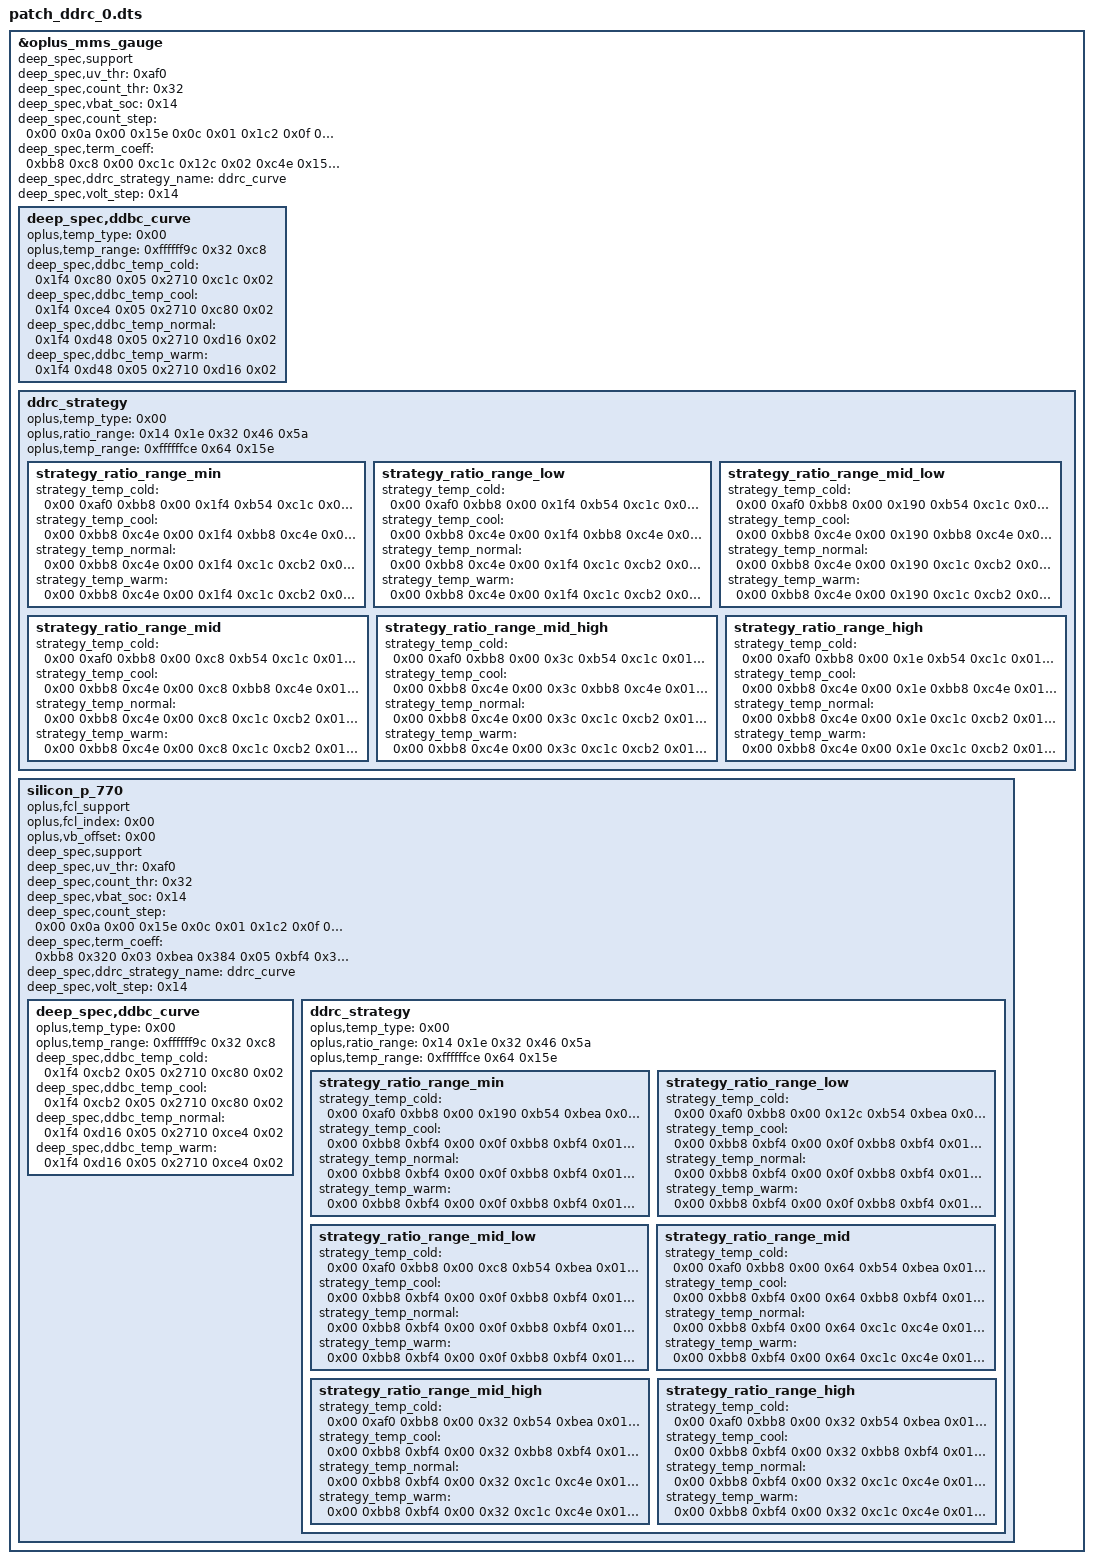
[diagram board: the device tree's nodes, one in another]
/dts-v1/;
/plugin/;

/ {
	fragment@0 {
		target = <&oplus_mms_gauge>;
		__overlay__ {
			deep_spec,support;
			deep_spec,uv_thr = <0xaf0>;
			deep_spec,count_thr = <0x32>;
			deep_spec,vbat_soc = <0x14>;
			deep_spec,count_step = <0x00 0x0a 0x00 0x15e 0x0c 0x01 0x1c2 0x0f 0x02 0x212 0x14 0x03>;
			deep_spec,term_coeff = <0xbb8 0xc8 0x00 0xc1c 0x12c 0x02 0xc4e 0x15e 0x03 0xcb2 0x1c2 0x05 0xce4 0x1f4 0x07 0xd2a 0x258 0x08 0xd48 0x258 0x08>;
			deep_spec,ddrc_strategy_name = "ddrc_curve";
			deep_spec,volt_step = <0x14>;
			
			deep_spec,ddbc_curve {
				oplus,temp_type = <0x00>;
				oplus,temp_range = <0xffffff9c 0x32 0xc8>;
				deep_spec,ddbc_temp_cold = <0x1f4 0xc80 0x05 0x2710 0xc1c 0x02>;
				deep_spec,ddbc_temp_cool = <0x1f4 0xce4 0x05 0x2710 0xc80 0x02>;
				deep_spec,ddbc_temp_normal = <0x1f4 0xd48 0x05 0x2710 0xd16 0x02>;
				deep_spec,ddbc_temp_warm = <0x1f4 0xd48 0x05 0x2710 0xd16 0x02>;
			};
			
			ddrc_strategy {
				oplus,temp_type = <0x00>;
				oplus,ratio_range = <0x14 0x1e 0x32 0x46 0x5a>;
				oplus,temp_range = <0xffffffce 0x64 0x15e>;
				
				strategy_ratio_range_min {
					strategy_temp_cold = <0x00 0xaf0 0xbb8 0x00 0x1f4 0xb54 0xc1c 0x01 0x3e8 0xbb8 0xc4e 0x02>;
					strategy_temp_cool = <0x00 0xbb8 0xc4e 0x00 0x1f4 0xbb8 0xc4e 0x01 0x3e8 0xc1c 0xcb2 0x02>;
					strategy_temp_normal = <0x00 0xbb8 0xc4e 0x00 0x1f4 0xc1c 0xcb2 0x01 0x3e8 0xc80 0xce4 0x02>;
					strategy_temp_warm = <0x00 0xbb8 0xc4e 0x00 0x1f4 0xc1c 0xcb2 0x01 0x3e8 0xc80 0xce4 0x02>;
				};
				
				strategy_ratio_range_low {
					strategy_temp_cold = <0x00 0xaf0 0xbb8 0x00 0x1f4 0xb54 0xc1c 0x01 0x3e8 0xbb8 0xc4e 0x02>;
					strategy_temp_cool = <0x00 0xbb8 0xc4e 0x00 0x1f4 0xbb8 0xc4e 0x01 0x3e8 0xc1c 0xcb2 0x02>;
					strategy_temp_normal = <0x00 0xbb8 0xc4e 0x00 0x1f4 0xc1c 0xcb2 0x01 0x3e8 0xc80 0xce4 0x02>;
					strategy_temp_warm = <0x00 0xbb8 0xc4e 0x00 0x1f4 0xc1c 0xcb2 0x01 0x3e8 0xc80 0xce4 0x02>;
				};
				
				strategy_ratio_range_mid_low {
					strategy_temp_cold = <0x00 0xaf0 0xbb8 0x00 0x190 0xb54 0xc1c 0x01 0x320 0xbb8 0xc4e 0x02>;
					strategy_temp_cool = <0x00 0xbb8 0xc4e 0x00 0x190 0xbb8 0xc4e 0x01 0x320 0xc1c 0xcb2 0x02>;
					strategy_temp_normal = <0x00 0xbb8 0xc4e 0x00 0x190 0xc1c 0xcb2 0x01 0x320 0xc80 0xce4 0x02>;
					strategy_temp_warm = <0x00 0xbb8 0xc4e 0x00 0x190 0xc1c 0xcb2 0x01 0x320 0xc80 0xce4 0x02>;
				};
				
				strategy_ratio_range_mid {
					strategy_temp_cold = <0x00 0xaf0 0xbb8 0x00 0xc8 0xb54 0xc1c 0x01 0x190 0xbb8 0xc4e 0x02 0x3e8 0xc1c 0xcb2 0x03>;
					strategy_temp_cool = <0x00 0xbb8 0xc4e 0x00 0xc8 0xbb8 0xc4e 0x01 0x190 0xc1c 0xcb2 0x02 0x3e8 0xc80 0xce4 0x03>;
					strategy_temp_normal = <0x00 0xbb8 0xc4e 0x00 0xc8 0xc1c 0xcb2 0x01 0x190 0xc80 0xce4 0x02 0x3e8 0xce4 0xd2a 0x03>;
					strategy_temp_warm = <0x00 0xbb8 0xc4e 0x00 0xc8 0xc1c 0xcb2 0x01 0x190 0xc80 0xce4 0x02 0x3e8 0xce4 0xd2a 0x03>;
				};
				
				strategy_ratio_range_mid_high {
					strategy_temp_cold = <0x00 0xaf0 0xbb8 0x00 0x3c 0xb54 0xc1c 0x01 0x78 0xbb8 0xc4e 0x02 0xdc 0xbb8 0xc4e 0x03 0x3e8 0xc1c 0xcb2 0x04>;
					strategy_temp_cool = <0x00 0xbb8 0xc4e 0x00 0x3c 0xbb8 0xc4e 0x01 0x78 0xc1c 0xcb2 0x02 0xdc 0xc80 0xce4 0x03 0x3e8 0xc80 0xce4 0x04>;
					strategy_temp_normal = <0x00 0xbb8 0xc4e 0x00 0x3c 0xc1c 0xcb2 0x01 0x78 0xc80 0xce4 0x02 0xdc 0xce4 0xd2a 0x03 0x3e8 0xd16 0xd48 0x04>;
					strategy_temp_warm = <0x00 0xbb8 0xc4e 0x00 0x3c 0xc1c 0xcb2 0x01 0x78 0xc80 0xce4 0x02 0xdc 0xce4 0xd2a 0x03 0x320 0xd16 0xd48 0x04>;
				};
				
				strategy_ratio_range_high {
					strategy_temp_cold = <0x00 0xaf0 0xbb8 0x00 0x1e 0xb54 0xc1c 0x01 0x3c 0xbb8 0xc4e 0x02 0x6e 0xc1c 0xcb2 0x03 0xa0 0xc1c 0xcb2 0x04>;
					strategy_temp_cool = <0x00 0xbb8 0xc4e 0x00 0x1e 0xbb8 0xc4e 0x01 0x3c 0xc1c 0xcb2 0x02 0x6e 0xc80 0xce4 0x03 0xa0 0xc80 0xce4 0x04>;
					strategy_temp_normal = <0x00 0xbb8 0xc4e 0x00 0x1e 0xc1c 0xcb2 0x01 0x3c 0xc80 0xce4 0x02 0x6e 0xce4 0xd2a 0x03 0xa0 0xd16 0xd48 0x04>;
					strategy_temp_warm = <0x00 0xbb8 0xc4e 0x00 0x1e 0xc1c 0xcb2 0x01 0x3c 0xc80 0xce4 0x02 0x6e 0xce4 0xd2a 0x03 0xa0 0xd16 0xd48 0x04>;
				};
			};
			
			silicon_p_770 {
				oplus,fcl_support;
				oplus,fcl_index = <0x00>;
				oplus,vb_offset = <0x00>;
				deep_spec,support;
				deep_spec,uv_thr = <0xaf0>;
				deep_spec,count_thr = <0x32>;
				deep_spec,vbat_soc = <0x14>;
				deep_spec,count_step = <0x00 0x0a 0x00 0x15e 0x0c 0x01 0x1c2 0x0f 0x02 0x212 0x14 0x03>;
				deep_spec,term_coeff = <0xbb8 0x320 0x03 0xbea 0x384 0x05 0xbf4 0x384 0x05 0xc4e 0x3e8 0x07 0xcb2 0x44c 0x09 0xd16 0x4b0 0x0a>;
				deep_spec,ddrc_strategy_name = "ddrc_curve";
				deep_spec,volt_step = <0x14>;
				
				deep_spec,ddbc_curve {
					oplus,temp_type = <0x00>;
					oplus,temp_range = <0xffffff9c 0x32 0xc8>;
					deep_spec,ddbc_temp_cold = <0x1f4 0xcb2 0x05 0x2710 0xc80 0x02>;
					deep_spec,ddbc_temp_cool = <0x1f4 0xcb2 0x05 0x2710 0xc80 0x02>;
					deep_spec,ddbc_temp_normal = <0x1f4 0xd16 0x05 0x2710 0xce4 0x02>;
					deep_spec,ddbc_temp_warm = <0x1f4 0xd16 0x05 0x2710 0xce4 0x02>;
				};
				
				ddrc_strategy {
					oplus,temp_type = <0x00>;
					oplus,ratio_range = <0x14 0x1e 0x32 0x46 0x5a>;
					oplus,temp_range = <0xffffffce 0x64 0x15e>;
					
					strategy_ratio_range_min {
						strategy_temp_cold = <0x00 0xaf0 0xbb8 0x00 0x190 0xb54 0xbea 0x01 0x320 0xbb8 0xbf4 0x02 0x4b0 0xc1c 0xc4e 0x03 0x640 0xc80 0xcb2 0x04 0x7d0 0xce4 0xd16 0x05>;
						strategy_temp_cool = <0x00 0xbb8 0xbf4 0x00 0x0f 0xbb8 0xbf4 0x01 0x1f4 0xbb8 0xbf4 0x02 0x3e8 0xc1c 0xc4e 0x03 0x5dc 0xc80 0xcb2 0x04 0x7d0 0xce4 0xd16 0x05>;
						strategy_temp_normal = <0x00 0xbb8 0xbf4 0x00 0x0f 0xbb8 0xbf4 0x01 0x1f4 0xc1c 0xc4e 0x02 0x3e8 0xc80 0xcb2 0x03 0x5dc 0xce4 0xd16 0x04>;
						strategy_temp_warm = <0x00 0xbb8 0xbf4 0x00 0x0f 0xbb8 0xbf4 0x01 0x1f4 0xc1c 0xc4e 0x02 0x3e8 0xc80 0xcb2 0x03 0x5dc 0xce4 0xd16 0x04>;
					};
					
					strategy_ratio_range_low {
						strategy_temp_cold = <0x00 0xaf0 0xbb8 0x00 0x12c 0xb54 0xbea 0x01 0x258 0xbb8 0xbf4 0x02 0x384 0xc1c 0xc4e 0x03 0x4b0 0xc80 0xcb2 0x04 0x640 0xce4 0xd16 0x05>;
						strategy_temp_cool = <0x00 0xbb8 0xbf4 0x00 0x0f 0xbb8 0xbf4 0x01 0x190 0xbb8 0xbf4 0x02 0x320 0xc1c 0xc4e 0x03 0x4b0 0xc80 0xcb2 0x04 0x640 0xce4 0xd16 0x05>;
						strategy_temp_normal = <0x00 0xbb8 0xbf4 0x00 0x0f 0xbb8 0xbf4 0x01 0x190 0xc1c 0xc4e 0x02 0x320 0xc80 0xcb2 0x03 0x4b0 0xce4 0xd16 0x04>;
						strategy_temp_warm = <0x00 0xbb8 0xbf4 0x00 0x0f 0xbb8 0xbf4 0x01 0x190 0xc1c 0xc4e 0x02 0x320 0xc80 0xcb2 0x03 0x4b0 0xce4 0xd16 0x04>;
					};
					
					strategy_ratio_range_mid_low {
						strategy_temp_cold = <0x00 0xaf0 0xbb8 0x00 0xc8 0xb54 0xbea 0x01 0x190 0xbb8 0xbf4 0x02 0x258 0xc1c 0xc4e 0x03 0x384 0xc80 0xcb2 0x04 0x4b0 0xce4 0xd16 0x05>;
						strategy_temp_cool = <0x00 0xbb8 0xbf4 0x00 0x0f 0xbb8 0xbf4 0x01 0x12c 0xbb8 0xbf4 0x02 0x258 0xc1c 0xc4e 0x03 0x384 0xc80 0xcb2 0x04 0x4b0 0xce4 0xd16 0x05>;
						strategy_temp_normal = <0x00 0xbb8 0xbf4 0x00 0x0f 0xbb8 0xbf4 0x01 0x12c 0xc1c 0xc4e 0x02 0x258 0xc80 0xcb2 0x03 0x384 0xce4 0xd16 0x04>;
						strategy_temp_warm = <0x00 0xbb8 0xbf4 0x00 0x0f 0xbb8 0xbf4 0x01 0x12c 0xc1c 0xc4e 0x02 0x258 0xc80 0xcb2 0x03 0x384 0xce4 0xd16 0x04>;
					};
					
					strategy_ratio_range_mid {
						strategy_temp_cold = <0x00 0xaf0 0xbb8 0x00 0x64 0xb54 0xbea 0x01 0x12c 0xbb8 0xbf4 0x02 0x1f4 0xc1c 0xc4e 0x03 0x2bc 0xc80 0xcb2 0x04 0x384 0xce4 0xd16 0x05>;
						strategy_temp_cool = <0x00 0xbb8 0xbf4 0x00 0x64 0xbb8 0xbf4 0x01 0x12c 0xc1c 0xc4e 0x02 0x258 0xc80 0xcb2 0x03 0x384 0xce4 0xd16 0x04>;
						strategy_temp_normal = <0x00 0xbb8 0xbf4 0x00 0x64 0xc1c 0xc4e 0x01 0x12c 0xc80 0xcb2 0x02 0x258 0xce4 0xd16 0x03>;
						strategy_temp_warm = <0x00 0xbb8 0xbf4 0x00 0x64 0xc1c 0xc4e 0x01 0x12c 0xc80 0xcb2 0x02 0x258 0xce4 0xd16 0x03>;
					};
					
					strategy_ratio_range_mid_high {
						strategy_temp_cold = <0x00 0xaf0 0xbb8 0x00 0x32 0xb54 0xbea 0x01 0x64 0xbb8 0xbf4 0x02 0x96 0xc1c 0xc4e 0x03 0x12c 0xc80 0xcb2 0x04 0x1f4 0xce4 0xd16 0x05>;
						strategy_temp_cool = <0x00 0xbb8 0xbf4 0x00 0x32 0xbb8 0xbf4 0x01 0x64 0xc1c 0xc4e 0x02 0x96 0xc80 0xcb2 0x03 0x12c 0xce4 0xd16 0x04>;
						strategy_temp_normal = <0x00 0xbb8 0xbf4 0x00 0x32 0xc1c 0xc4e 0x01 0x64 0xc80 0xcb2 0x02 0x96 0xce4 0xd16 0x03>;
						strategy_temp_warm = <0x00 0xbb8 0xbf4 0x00 0x32 0xc1c 0xc4e 0x01 0x64 0xc80 0xcb2 0x02 0x96 0xce4 0xd16 0x03>;
					};
					
					strategy_ratio_range_high {
						strategy_temp_cold = <0x00 0xaf0 0xbb8 0x00 0x32 0xb54 0xbea 0x01 0x64 0xbb8 0xbf4 0x02 0x96 0xc1c 0xc4e 0x03 0x12c 0xc80 0xcb2 0x04 0x1f4 0xce4 0xd16 0x05>;
						strategy_temp_cool = <0x00 0xbb8 0xbf4 0x00 0x32 0xbb8 0xbf4 0x01 0x64 0xc1c 0xc4e 0x02 0x96 0xc80 0xcb2 0x03 0x12c 0xce4 0xd16 0x04>;
						strategy_temp_normal = <0x00 0xbb8 0xbf4 0x00 0x32 0xc1c 0xc4e 0x01 0x64 0xc80 0xcb2 0x02 0x96 0xce4 0xd16 0x03>;
						strategy_temp_warm = <0x00 0xbb8 0xbf4 0x00 0x32 0xc1c 0xc4e 0x01 0x64 0xc80 0xcb2 0x02 0x96 0xce4 0xd16 0x03>;
					};
				};
			};
		};
	};
};
